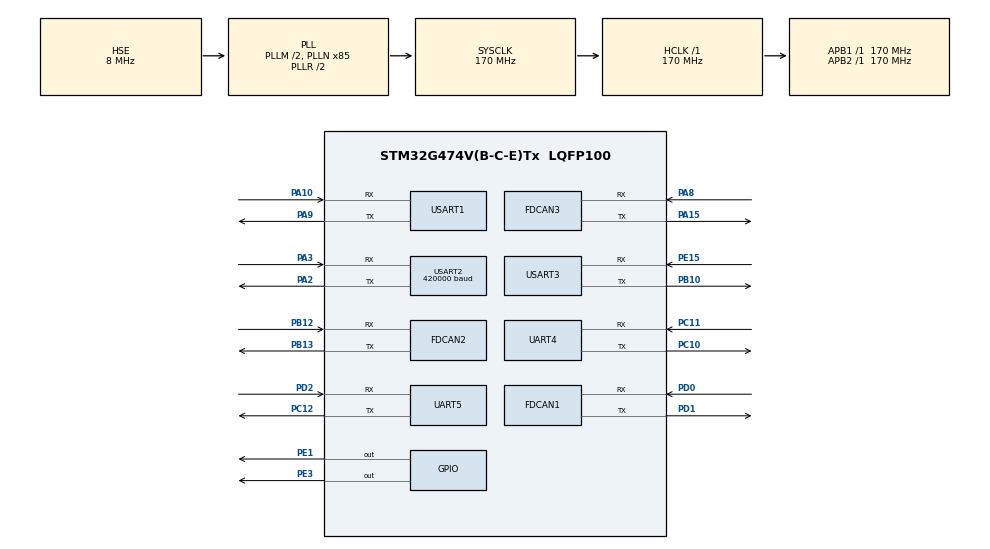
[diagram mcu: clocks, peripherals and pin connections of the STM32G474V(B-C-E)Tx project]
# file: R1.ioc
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Dma.Request0=USART2_RX
Dma.USART2_RX.0.Direction=DMA_PERIPH_TO_MEMORY
Dma.USART2_RX.0.EventEnable=DISABLE
Dma.USART2_RX.0.Instance=DMA1_Channel1
Dma.USART2_RX.0.MemDataAlignment=DMA_MDATAALIGN_BYTE
Dma.USART2_RX.0.MemInc=DMA_MINC_ENABLE
Dma.USART2_RX.0.Mode=DMA_CIRCULAR
Dma.USART2_RX.0.PeriphDataAlignment=DMA_PDATAALIGN_BYTE
Dma.USART2_RX.0.PeriphInc=DMA_PINC_DISABLE
Dma.USART2_RX.0.Polarity=HAL_DMAMUX_REQ_GEN_RISING
Dma.USART2_RX.0.Priority=DMA_PRIORITY_LOW
Dma.USART2_RX.0.RequestNumber=1
Dma.USART2_RX.0.SignalID=NONE
Dma.USART2_RX.0.SyncEnable=DISABLE
Dma.USART2_RX.0.SyncPolarity=HAL_DMAMUX_SYNC_NO_EVENT
Dma.USART2_RX.0.SyncRequestNumber=1
Dma.USART2_RX.0.SyncSignalID=NONE
FDCAN1.AutoRetransmission=ENABLE
FDCAN1.CalculateBaudRateNominal=1000000
FDCAN1.CalculateTimeBitNominal=1000
FDCAN1.CalculateTimeQuantumNominal=100.0
FDCAN1.NominalPrescaler=17
FDCAN1.NominalTimeSeg1=7
FDCAN1.NominalTimeSeg2=2
FDCAN1.StdFiltersNbr=1
FDCAN2.AutoRetransmission=ENABLE
FDCAN2.CalculateBaudRateNominal=1000000
FDCAN2.CalculateTimeBitNominal=1000
FDCAN2.CalculateTimeQuantumNominal=100.0
FDCAN2.NominalPrescaler=17
FDCAN2.NominalTimeSeg1=7
FDCAN2.NominalTimeSeg2=2
FDCAN2.StdFiltersNbr=1
FDCAN3.AutoRetransmission=ENABLE
FDCAN3.CalculateBaudRateNominal=1000000
FDCAN3.CalculateTimeBitNominal=1000
FDCAN3.CalculateTimeQuantumNominal=100.0
FDCAN3.NominalPrescaler=17
FDCAN3.NominalTimeSeg1=7
FDCAN3.NominalTimeSeg2=2
FDCAN3.StdFiltersNbr=1
Mcu.Family=STM32G4
Mcu.Name=STM32G474V(B-C-E)Tx
Mcu.Package=LQFP100
NVIC.DMA1_Channel1_IRQn=true\:5\:0\:false\:false\:true\:false\:true\:true
NVIC.FDCAN1_IT0_IRQn=true\:0\:0\:false\:false\:true\:true\:true\:true
NVIC.FDCAN2_IT0_IRQn=true\:0\:0\:false\:false\:true\:true\:true\:true
NVIC.FDCAN3_IT0_IRQn=true\:0\:0\:false\:false\:true\:true\:true\:true
NVIC.PriorityGroup=NVIC_PRIORITYGROUP_4
NVIC.TIM6_DAC_IRQn=true\:15\:0\:false\:false\:true\:false\:true\:true
NVIC.TimeBase=TIM6_DAC_IRQn
NVIC.TimeBaseIP=TIM6
NVIC.USART2_IRQn=true\:5\:0\:true\:false\:true\:true\:true\:true
NVIC.USART3_IRQn=true\:6\:0\:true\:false\:true\:true\:true\:true
PA10.Mode=Asynchronous
PA10.Signal=USART1_RX
PA13.Mode=Serial_Wire
PA13.Signal=SYS_JTMS-SWDIO
PA14.Mode=Serial_Wire
PA14.Signal=SYS_JTCK-SWCLK
PA15.Mode=FDCAN_Activate
PA15.Signal=FDCAN3_TX
PA2.Mode=Asynchronous
PA2.Signal=USART2_TX
PA3.Mode=Asynchronous
PA3.Signal=USART2_RX
PA8.Mode=FDCAN_Activate
PA8.Signal=FDCAN3_RX
PA9.Mode=Asynchronous
PA9.Signal=USART1_TX
PB10.Mode=Asynchronous
PB10.Signal=USART3_TX
PB12.Mode=FDCAN_Activate
PB12.Signal=FDCAN2_RX
PB13.Mode=FDCAN_Activate
PB13.Signal=FDCAN2_TX
PC10.Mode=Asynchronous
PC10.Signal=UART4_TX
PC11.Mode=Asynchronous
PC11.Signal=UART4_RX
PC12.Mode=Asynchronous
PC12.Signal=UART5_TX
PD0.Mode=FDCAN_Activate
PD0.Signal=FDCAN1_RX
PD1.Mode=FDCAN_Activate
PD1.Signal=FDCAN1_TX
PD2.Mode=Asynchronous
PD2.Signal=UART5_RX
PE1.GPIO_Speed=GPIO_SPEED_FREQ_HIGH
PE1.PinState=GPIO_PIN_RESET
PE1.Signal=GPIO_Output
PE15.Mode=Asynchronous
PE15.Signal=USART3_RX
PE3.GPIO_Speed=GPIO_SPEED_FREQ_HIGH
PE3.Signal=GPIO_Output
PF0-OSC_IN.Mode=HSE-External-Oscillator
PF0-OSC_IN.Signal=RCC_OSC_IN
PF1-OSC_OUT.Mode=HSE-External-Oscillator
PF1-OSC_OUT.Signal=RCC_OSC_OUT
ProjectManager.HeapSize=0x200
ProjectManager.StackSize=0x400
ProjectManager.TargetToolchain=MDK-ARM V5.32
RCC.ADC12Freq_Value=170000000
RCC.ADC345Freq_Value=170000000
RCC.AHBFreq_Value=170000000
RCC.APB1Freq_Value=170000000
RCC.APB1TimFreq_Value=170000000
RCC.APB2Freq_Value=170000000
RCC.APB2TimFreq_Value=170000000
RCC.CortexFreq_Value=170000000
RCC.EXTERNAL_CLOCK_VALUE=12288000
RCC.HCLKFreq_Value=170000000
RCC.HSE_VALUE=8000000
RCC.HSI48_VALUE=48000000
RCC.HSI_VALUE=16000000
RCC.LSE_VALUE=32768
RCC.PLLM=RCC_PLLM_DIV2
RCC.PLLN=85
RCC.PLLSourceVirtual=RCC_PLLSOURCE_HSE
RCC.SYSCLKFreq_VALUE=170000000
RCC.SYSCLKSource=RCC_SYSCLKSOURCE_PLLCLK
RCC.USBFreq_Value=170000000
RCC.VCOOutputFreq_Value=340000000
USART1.VirtualMode-Asynchronous=VM_ASYNC
USART2.BaudRate=420000
USART2.VirtualMode-Asynchronous=VM_ASYNC
USART3.VirtualMode-Asynchronous=VM_ASYNC
VP_SYS_VS_DBSignals.Mode=DisableDeadBatterySignals
VP_SYS_VS_tim6.Mode=TIM6
board=custom

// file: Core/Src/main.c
/* USER CODE BEGIN Header */
/**
  ******************************************************************************
  * @file           : main.c
  * @brief          : Main program body
  ******************************************************************************
  * @attention
  *
  * Copyright (c) 2026 STMicroelectronics.
  * All rights reserved.
  *
  * This software is licensed under terms that can be found in the LICENSE file
  * in the root directory of this software component.
  * If no LICENSE file comes with this software, it is provided AS-IS.
  *
  ******************************************************************************
  */
/* USER CODE END Header */
#include "main.h"
#include "dma.h"
#include "fdcan.h"
#include "usart.h"
#include "gpio.h"

/* USER CODE BEGIN Includes */
#include "chassic_motor.h"
#include "remote_control.h"
#include "motor_3508.h"
#include "motor_dm.h"
#include "arm_motor.h"
#include "claw_motor.h"
#include "freertos_start.h"
#include "arm_math.h"
/* USER CODE END Includes */

void SystemClock_Config(void);

int main(void)
{

  /* MCU Configuration--------------------------------------------------------*/

  /* Reset of all peripherals, Initializes the Flash interface and the Systick. */
  HAL_Init();

  /* Configure the system clock */
  SystemClock_Config();

  /* Initialize all configured peripherals */
  MX_GPIO_Init();
  MX_DMA_Init();
  MX_FDCAN1_Init();
  MX_FDCAN2_Init();
  MX_FDCAN3_Init();
  MX_USART1_UART_Init();
  MX_USART2_UART_Init();
  MX_USART3_UART_Init();
  MX_UART4_Init();
  MX_UART5_Init();
  /* USER CODE BEGIN 2 */

  FDCAN1_Filter_Config();
  FDCAN2_Filter_Config();
  FDCAN3_Filter_Config();

  PID_Speed_Init(&motor_speed);
  PID_Angle_Init(&motor_angle);

  freertos_start();

  /* USER CODE END 2 */

  /* Infinite loop */
  while (1)
  {

  }
}

void SystemClock_Config(void)
{
  RCC_OscInitTypeDef RCC_OscInitStruct = {0};
  RCC_ClkInitTypeDef RCC_ClkInitStruct = {0};

  /** Configure the main internal regulator output voltage
  */
  HAL_PWREx_ControlVoltageScaling(PWR_REGULATOR_VOLTAGE_SCALE1_BOOST);

  /** Initializes the RCC Oscillators according to the specified parameters
  * in the RCC_OscInitTypeDef structure.
  */
  RCC_OscInitStruct.OscillatorType = RCC_OSCILLATORTYPE_HSE;
  RCC_OscInitStruct.HSEState = RCC_HSE_ON;
  RCC_OscInitStruct.PLL.PLLState = RCC_PLL_ON;
  RCC_OscInitStruct.PLL.PLLSource = RCC_PLLSOURCE_HSE;
  RCC_OscInitStruct.PLL.PLLM = RCC_PLLM_DIV2;
  RCC_OscInitStruct.PLL.PLLN = 85;
  RCC_OscInitStruct.PLL.PLLP = RCC_PLLP_DIV2;
  RCC_OscInitStruct.PLL.PLLQ = RCC_PLLQ_DIV2;
  RCC_OscInitStruct.PLL.PLLR = RCC_PLLR_DIV2;
  if (HAL_RCC_OscConfig(&RCC_OscInitStruct) != HAL_OK)
  {
    Error_Handler();
  }

  /** Initializes the CPU, AHB and APB buses clocks
  */
  RCC_ClkInitStruct.ClockType = RCC_CLOCKTYPE_HCLK|RCC_CLOCKTYPE_SYSCLK
                              |RCC_CLOCKTYPE_PCLK1|RCC_CLOCKTYPE_PCLK2;
  RCC_ClkInitStruct.SYSCLKSource = RCC_SYSCLKSOURCE_PLLCLK;
  RCC_ClkInitStruct.AHBCLKDivider = RCC_SYSCLK_DIV1;
  RCC_ClkInitStruct.APB1CLKDivider = RCC_HCLK_DIV1;
  RCC_ClkInitStruct.APB2CLKDivider = RCC_HCLK_DIV1;

  if (HAL_RCC_ClockConfig(&RCC_ClkInitStruct, FLASH_LATENCY_4) != HAL_OK)
  {
    Error_Handler();
  }
}

void HAL_TIM_PeriodElapsedCallback(TIM_HandleTypeDef *htim)
{
  if (htim->Instance == TIM6)
  {
    HAL_IncTick();
  }
}

void Error_Handler(void)
{
  __disable_irq();
  while (1)
  {
  }
}
